AUTOSAR XML (schema 00044)
package /E40_Platform_System_SystemPackage/Components
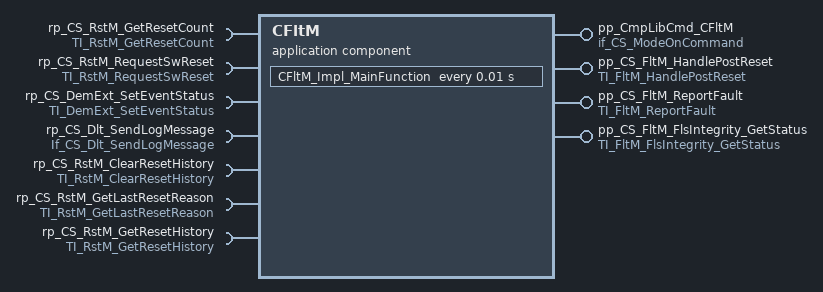
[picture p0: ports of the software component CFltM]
  application sw component type CFltM
    provide port pp_CmpLibCmd_CFltM: server-com-spec{operation=Impl_OnCommand, queue-length=1}, provided-interface=if_CS_ModeOnCommand
    require port rp_CS_RstM_GetResetCount: client-com-spec=RstM_GetResetCount, required-interface=TI_RstM_GetResetCount
    require port rp_CS_RstM_RequestSwReset: client-com-spec=RstM_RequestSwReset, required-interface=TI_RstM_RequestSwReset
    require port rp_CS_DemExt_SetEventStatus: client-com-spec=DemExt_SetEventStatus, required-interface=TI_DemExt_SetEventStatus
    provide port pp_CS_FltM_HandlePostReset: server-com-spec{operation=FltM_HandlePostReset, queue-length=1}, provided-interface=TI_FltM_HandlePostReset
    provide port pp_CS_FltM_ReportFault: server-com-spec{operation=FltM_ReportFault, queue-length=1}, provided-interface=TI_FltM_ReportFault
    4 x require port:
      rp_CS_Dlt_SendLogMessage: client-com-spec=SendLogMessage, required-interface=If_CS_Dlt_SendLogMessage
      rp_CS_RstM_ClearResetHistory: required-interface=TI_RstM_ClearResetHistory
      rp_CS_RstM_GetLastResetReason: client-com-spec=RstM_GetLastResetReason, required-interface=TI_RstM_GetLastResetReason
      rp_CS_RstM_GetResetHistory: client-com-spec=RstM_GetResetHistory, required-interface=TI_RstM_GetResetHistory
    provide port pp_CS_FltM_FlsIntegrity_GetStatus: server-com-spec{operation=FltM_FlsIntegrity_GetStatus, queue-length=1}, provided-interface=TI_FltM_FlsIntegrity_GetStatus
    behavior IB_CFltM
      operation invoked event OIE_pp_CmpLibCmd_CFltM_CFltM_Impl_OnCommandTrigByImpl_OnCommand: start-on-event=CFltM_Impl_OnCommand, operation=pp_CmpLibCmd_CFltM.Impl_OnCommand
      operation invoked event OIE_pp_CS_FltM_HandlePostReset_FltM_HandlePostResetTrigByFltM_HandlePostReset: start-on-event=FltM_HandlePostReset, operation=pp_CS_FltM_HandlePostReset.FltM_HandlePostReset
      operation invoked event OIE_pp_CS_FltM_ReportFault_FltM_ReportFaultTrigByFltM_ReportFault: start-on-event=FltM_ReportFault, operation=pp_CS_FltM_ReportFault.FltM_ReportFault
      timing event TECFltM_Impl_MainFunction: start-on-event=CFltM_Impl_MainFunction, period=0.01
      operation invoked event OIE_pp_CS_FltM_FlsIntegrity_GetStatus_FltM_FlsIntegrity_GetStatusTrigByFltM_FlsIntegrity_GetStatus: start-on-event=FltM_FlsIntegrity_GetStatus, operation=pp_CS_FltM_FlsIntegrity_GetStatus.FltM_FlsIntegrity_GetStatus
      port-api-options:
        enable-take-address=false, indirect-api=false, port=pp_CmpLibCmd_CFltM
        enable-take-address=false, indirect-api=false, port=rp_CS_RstM_GetResetCount
        enable-take-address=false, indirect-api=false, port=rp_CS_RstM_RequestSwReset
        enable-take-address=false, indirect-api=false, port=rp_CS_DemExt_SetEventStatus
        enable-take-address=false, indirect-api=false, port=pp_CS_FltM_HandlePostReset
        enable-take-address=false, indirect-api=false, port=pp_CS_FltM_ReportFault
        enable-take-address=false, indirect-api=false, port=rp_CS_Dlt_SendLogMessage
        enable-take-address=false, indirect-api=false, port=rp_CS_RstM_ClearResetHistory
        enable-take-address=false, indirect-api=false, port=rp_CS_RstM_GetLastResetReason
        enable-take-address=false, indirect-api=false, port=rp_CS_RstM_GetResetHistory
        enable-take-address=false, indirect-api=false, port=pp_CS_FltM_FlsIntegrity_GetStatus
      5 x runnable, all with can-be-invoked-concurrently=true:
        CFltM_Impl_OnCommand
          6 x sync call:
            OA_rp_CS_RstM_GetResetCount_RstM_GetResetCount: operation=rp_CS_RstM_GetResetCount.RstM_GetResetCount
            OA_rp_CS_RstM_RequestSwReset_RstM_RequestSwReset: operation=rp_CS_RstM_RequestSwReset.RstM_RequestSwReset
            OA_rp_CS_DemExt_SetEventStatus_DemExt_SetEventStatus: operation=rp_CS_DemExt_SetEventStatus.DemExt_SetEventStatus
            OA_rp_CS_RstM_GetLastResetReason_RstM_GetLastResetReason: operation=rp_CS_RstM_GetLastResetReason.RstM_GetLastResetReason
            OA_rp_CS_RstM_GetResetHistory_RstM_GetResetHistory: operation=rp_CS_RstM_GetResetHistory.RstM_GetResetHistory
            OA_rp_CS_RstM_ClearResetHistory_RstM_ClearResetHistory: operation=rp_CS_RstM_ClearResetHistory.RstM_ClearResetHistory
        FltM_HandlePostReset
          6 x sync call:
            OA_rp_CS_DemExt_SetEventStatus_DemExt_SetEventStatus: operation=rp_CS_DemExt_SetEventStatus.DemExt_SetEventStatus
            OA_rp_CS_RstM_GetResetCount_RstM_GetResetCount: operation=rp_CS_RstM_GetResetCount.RstM_GetResetCount
            OA_rp_CS_RstM_RequestSwReset_RstM_RequestSwReset: operation=rp_CS_RstM_RequestSwReset.RstM_RequestSwReset
            OA_rp_CS_RstM_GetLastResetReason_RstM_GetLastResetReason: operation=rp_CS_RstM_GetLastResetReason.RstM_GetLastResetReason
            OA_rp_CS_RstM_GetResetHistory_RstM_GetResetHistory: operation=rp_CS_RstM_GetResetHistory.RstM_GetResetHistory
            OA_rp_CS_RstM_ClearResetHistory_RstM_ClearResetHistory: operation=rp_CS_RstM_ClearResetHistory.RstM_ClearResetHistory
        FltM_ReportFault
          6 x sync call:
            OA_rp_CS_DemExt_SetEventStatus_DemExt_SetEventStatus: operation=rp_CS_DemExt_SetEventStatus.DemExt_SetEventStatus
            OA_rp_CS_RstM_GetResetCount_RstM_GetResetCount: operation=rp_CS_RstM_GetResetCount.RstM_GetResetCount
            OA_rp_CS_RstM_RequestSwReset_RstM_RequestSwReset: operation=rp_CS_RstM_RequestSwReset.RstM_RequestSwReset
            OA_rp_CS_RstM_GetLastResetReason_RstM_GetLastResetReason: operation=rp_CS_RstM_GetLastResetReason.RstM_GetLastResetReason
            OA_rp_CS_RstM_GetResetHistory_RstM_GetResetHistory: operation=rp_CS_RstM_GetResetHistory.RstM_GetResetHistory
            OA_rp_CS_RstM_ClearResetHistory_RstM_ClearResetHistory: operation=rp_CS_RstM_ClearResetHistory.RstM_ClearResetHistory
        CFltM_Impl_MainFunction
          6 x sync call:
            OA_rp_CS_DemExt_SetEventStatus_DemExt_SetEventStatus: operation=rp_CS_DemExt_SetEventStatus.DemExt_SetEventStatus
            OA_rp_CS_RstM_ClearResetHistory_RstM_ClearResetHistory: operation=rp_CS_RstM_ClearResetHistory.RstM_ClearResetHistory
            OA_rp_CS_RstM_GetLastResetReason_RstM_GetLastResetReason: operation=rp_CS_RstM_GetLastResetReason.RstM_GetLastResetReason
            OA_rp_CS_RstM_GetResetCount_RstM_GetResetCount: operation=rp_CS_RstM_GetResetCount.RstM_GetResetCount
            OA_rp_CS_RstM_GetResetHistory_RstM_GetResetHistory: operation=rp_CS_RstM_GetResetHistory.RstM_GetResetHistory
            OA_rp_CS_RstM_RequestSwReset_RstM_RequestSwReset: operation=rp_CS_RstM_RequestSwReset.RstM_RequestSwReset
        FltM_FlsIntegrity_GetStatus
          6 x sync call:
            OA_rp_CS_DemExt_SetEventStatus_DemExt_SetEventStatus: operation=rp_CS_DemExt_SetEventStatus.DemExt_SetEventStatus
            OA_rp_CS_RstM_ClearResetHistory_RstM_ClearResetHistory: operation=rp_CS_RstM_ClearResetHistory.RstM_ClearResetHistory
            OA_rp_CS_RstM_GetLastResetReason_RstM_GetLastResetReason: operation=rp_CS_RstM_GetLastResetReason.RstM_GetLastResetReason
            OA_rp_CS_RstM_GetResetCount_RstM_GetResetCount: operation=rp_CS_RstM_GetResetCount.RstM_GetResetCount
            OA_rp_CS_RstM_GetResetHistory_RstM_GetResetHistory: operation=rp_CS_RstM_GetResetHistory.RstM_GetResetHistory
            OA_rp_CS_RstM_RequestSwReset_RstM_RequestSwReset: operation=rp_CS_RstM_RequestSwReset.RstM_RequestSwReset
  swc implementation IMPL_CFltM: behavior=IB_CFltM
